# MEC1322 register map
Vendor: Microchip Technology Inc.; Series: ARMCM4F; File version: 1.0
CPU: CM4 r1p0, little endian, MPU, FPU, 3 interrupt priority bits
Registers are 32-bit, read-write, reset 0x0 unless marked. A register's access mark holds for its fields unless they carry their own. Offsets are from the block's base; [hi:lo] are bit positions.

## FAN — The RPM-PWM Interface is an RPM based Fan Control Algorithm that monitors the fan's speed and automatically adjusts the drive to maintain the desired fan speed. This. RPM based Fan Control Algorithm controls a PWM output based on a tachometer input.
Base 0x4000A000
0x00 SETTING 8-bit — The Fan Driver Setting used to control the output of the Fan Driver. The contents of the register represent the weighting of each bit in determining the final duty cycle. The output drive for a PWM output is given by the following equation: - Drive = (FAN_SETTING VALUE/255) x 100%.
0x01 PWM_DIVIDE 8-bit — The final PWM frequency is derived as the base frequency divided by the value of this register as shown in the equation below: - PWM_Frequency = base_clk / PWM_D. Where: - base_clk = The base frequency set by the PWMx_CFG[1:0] bits - PWM_D = the divide setting set by the PWM Divide Register.
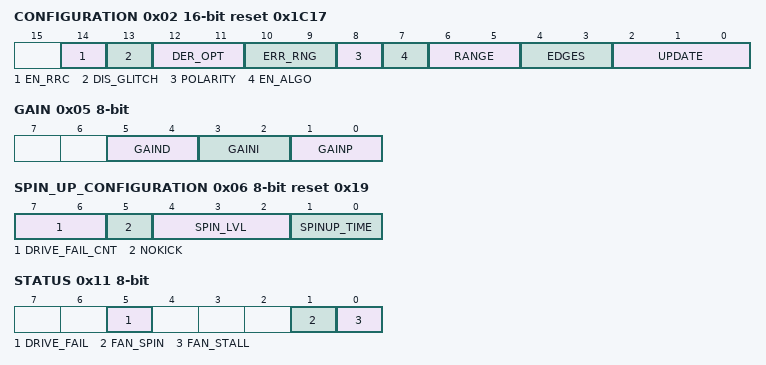
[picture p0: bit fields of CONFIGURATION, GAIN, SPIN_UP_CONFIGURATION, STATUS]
0x02 CONFIGURATION 16-bit reset 0x1C17 — The Fan Configuration Register controls the general operation of the RPM based Fan Control Algorithm used by the fan driver.
  [14] EN_RRC — Enables the ramp rate control circuitry during the Manual Mode of operation.
  [13] DIS_GLITCH — Disables the low pass glitch filter that removes high frequency noise injected on the TACH pin. 0 (default) - The glitch filter is enabled. 1 - The glitch filter is disabled.
  [12:11] DER_OPT — Control some of the advanced options that affect the derivative portion of the RPM based fan control algorithm
  [10:9] ERR_RNG — Control some of the advanced options that affect the error window.
  [8] POLARITY — Determines the polarity of the PWM driver. 0 (default) - the Polarity of the PWM driver is normal. 1 - The Polarity of the PWM driver is inverted.
  [7] EN_ALGO — Enables the RPM based Fan Control Algorithm.
  [6:5] RANGE — Adjusts the range of reported and programmed tachometer reading values.
  [4:3] EDGES — Determines the minimum number of edges that must be detected on the TACH signal to determine a single rotation. A typical fan measured 5 edges (for a 2-pole fan).
  [2:0] UPDATE — Determines the base time between fan driver updates.
0x05 GAIN 8-bit — Gain Register stores the gain terms used by the proportional and integral portions of the RPM based Fan Control Algorithm.
  [5:4] GAIND — derivative gain term
  [3:2] GAINI — derivative gain term
  [1:0] GAINP — derivative gain term
0x06 SPIN_UP_CONFIGURATION 8-bit reset 0x19 — The Fan Spin Up Configuration Register controls the settings of Spin Up Routine.
  [7:6] DRIVE_FAIL_CNT — Determines how many update cycles are used for the Drive Fail detection function
  [5] NOKICK — Determines if the Spin Up Routine will drive the fan to 100% duty cycle for 1/4 of the programmed spin up time before driving it at the programmed level.
  [4:2] SPIN_LVL — Determines the final drive level that is used by the Spin Up Routine
  [1:0] SPINUP_TIME — Determines the maximum Spin Time that the Spin Up Routine will run for
0x07 STEP 8-bit reset 0x10 — FAN_STEP[5:0] The Fan Step value represents the maximum step size the fan driver will take between update times
0x08 MINIMUM_DRIVE 8-bit reset 0x66 — the minimum drive setting for the RPM based Fan Control Algorithm.
0x09 VALID_TACH_COUNT 8-bit reset 0xF5 — The maximum TACH Reading Register value to indicate that the fan is spinning properly.
0x0A DRIVE_FAIL_BAND 16-bit (reset mask 0xFF) — [15:3] The number of Tach counts used by the Fan Drive Fail detection circuitry
0x0C TACH_TARGET 16-bit reset 0xFFF8 — [12:0] The target tachometer value.
0x0E TACH_READING 8-bit reset 0xFFF8 — [15:3] The current tachometer reading value.
0x10 DRIVER_BASE_FREQUENCY 8-bit — [1:0] Determines the frequency range of the PWM fan driver
0x11 STATUS 8-bit — The bits in this register are routed to interrupts.
  [5] DRIVE_FAIL — 0- The RPM-based Fan Speed Control Algorithm can drive Fan to the desired target setting. 1- The RPM-based Fan Speed Control Algorithm cannot drive Fan to the desired target setting at maximum drive.(R/WC)
  [1] FAN_SPIN — 0 - The Spin up Routine for the Fan detected a valid tachometer reading within its maximum time window. 1 - The Spin up Routine for the Fan could not detect a valid tachometer reading within its maximum time window. (R/WC)
  [0] FAN_STALL — 0 - Stalled fan not detected. 1 - Stalled fan detected. (R/WC)
